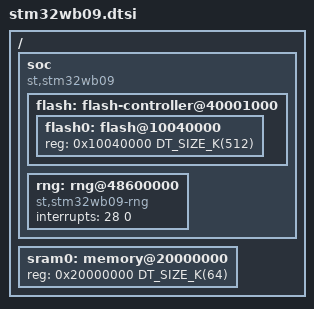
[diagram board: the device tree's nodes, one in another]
/*
 * Copyright (c) 2024 STMicroelectronics
 *
 * SPDX-License-Identifier: Apache-2.0
 */

#include <st/wb0/stm32wb05_09.dtsi>

/ {
	soc {
		compatible = "st,stm32wb09", "st,stm32wb0", "simple-bus";

		flash: flash-controller@40001000 {
			flash0: flash@10040000 {
				reg = <0x10040000 DT_SIZE_K(512)>;
			};
		};

		rng: rng@48600000 {
			/* Unlike all other MCUs in the STM32WB0 series,
			 * the STM32WB09 uses a different and unusual TRNG
			 * peripheral, which requires a separate driver.
			 * It is mapped at the same address and controlled
			 * by the same RCC register field, though. Change
			 * only the `compatible` to make everything work.
			 */
			/delete-property/ compatible;
			compatible = "st,stm32wb09-rng";

			/* This TRNG has an interrupt line, too. */
			interrupts = <28 0>;
		};
	};

	sram0: memory@20000000 {
		reg = <0x20000000 DT_SIZE_K(64)>;
	};
};
